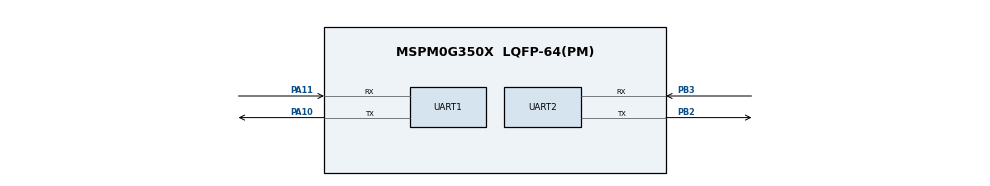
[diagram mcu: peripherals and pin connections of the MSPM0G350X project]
/**
 * @cliArgs --device "MSPM0G350X" --package "LQFP-64(PM)" --part "Default" --product "mspm0_sdk@2.01.00.03"
 * @versions {"tool":"1.20.0+3587"}
 */

/**
 * Import the modules used in this configuration.
 */
const GPIO    = scripting.addModule("/ti/driverlib/GPIO", {}, false);
const GPIO1   = GPIO.addInstance();
const GPIO2   = GPIO.addInstance();
const SYSCTL  = scripting.addModule("/ti/driverlib/SYSCTL");
const SYSTICK = scripting.addModule("/ti/driverlib/SYSTICK");
const TIMER   = scripting.addModule("/ti/driverlib/TIMER", {}, false);
const TIMER1  = TIMER.addInstance();
const UART    = scripting.addModule("/ti/driverlib/UART", {}, false);
const UART1   = UART.addInstance();
const UART2   = UART.addInstance();

/**
 * Write custom configuration values to the imported modules.
 */
const gate7  = system.clockTree["MFCLKGATE"];
gate7.enable = true;

GPIO1.$name                          = "LED1";
GPIO1.associatedPins[0].$name        = "PIN_0";
GPIO1.associatedPins[0].assignedPort = "PORTA";
GPIO1.associatedPins[0].assignedPin  = "0";

const Board = scripting.addModule("/ti/driverlib/Board", {}, false);

GPIO2.$name                          = "KEY";
GPIO2.associatedPins[0].$name        = "PIN_21";
GPIO2.associatedPins[0].direction    = "INPUT";
GPIO2.associatedPins[0].assignedPort = "PORTB";
GPIO2.associatedPins[0].assignedPin  = "21";

SYSCTL.forceDefaultClkConfig = true;
SYSCTL.clockTreeEn           = true;

SYSTICK.periodEnable  = true;
SYSTICK.period        = 32;
SYSTICK.systickEnable = true;

TIMER1.$name            = "TIMER_0";
TIMER1.timerClkDiv      = 8;
TIMER1.timerClkPrescale = 200;
TIMER1.timerPeriod      = "5 ms";
TIMER1.timerStartTimer  = true;
TIMER1.interrupts       = ["ZERO"];
TIMER1.timerMode        = "PERIODIC";

UART1.$name                    = "UART_0";
UART1.uartClkSrc               = "MFCLK";
UART1.enabledInterrupts        = ["RX"];
UART1.peripheral.rxPin.$assign = "PA11";
UART1.peripheral.txPin.$assign = "PA10";
UART1.txPinConfig.$name        = "ti_driverlib_gpio_GPIOPinGeneric0";
UART1.rxPinConfig.$name        = "ti_driverlib_gpio_GPIOPinGeneric1";

UART2.$name                    = "UART_1";
UART2.enabledInterrupts        = ["RX"];
UART2.targetBaudRate           = 460800;
UART2.peripheral.rxPin.$assign = "PB3";
UART2.peripheral.txPin.$assign = "PB2";
UART2.txPinConfig.$name        = "ti_driverlib_gpio_GPIOPinGeneric2";
UART2.rxPinConfig.$name        = "ti_driverlib_gpio_GPIOPinGeneric3";

/**
 * Pinmux solution for unlocked pins/peripherals. This ensures that minor changes to the automatic solver in a future
 * version of the tool will not impact the pinmux you originally saw.  These lines can be completely deleted in order to
 * re-solve from scratch.
 */
GPIO1.associatedPins[0].pin.$suggestSolution = "PA0";
Board.peripheral.$suggestSolution            = "DEBUGSS";
Board.peripheral.swclkPin.$suggestSolution   = "PA20";
Board.peripheral.swdioPin.$suggestSolution   = "PA19";
GPIO2.associatedPins[0].pin.$suggestSolution = "PB21";
TIMER1.peripheral.$suggestSolution           = "TIMA0";
UART1.peripheral.$suggestSolution            = "UART0";
UART2.peripheral.$suggestSolution            = "UART3";
